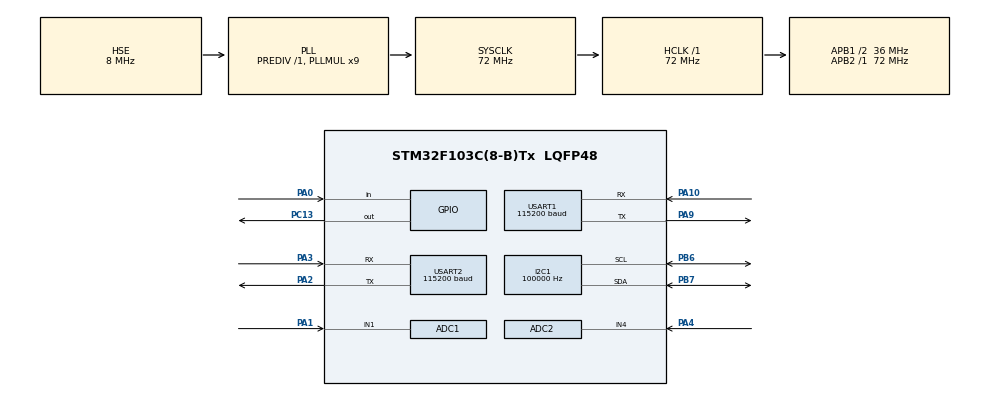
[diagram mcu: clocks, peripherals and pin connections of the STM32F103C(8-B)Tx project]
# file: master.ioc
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ADC1.Channel-0\#ChannelRegularConversion=ADC_CHANNEL_1
ADC1.ContinuousConvMode=ENABLE
ADC1.NbrOfConversionFlag=1
ADC1.Rank-0\#ChannelRegularConversion=1
ADC1.SamplingTime-0\#ChannelRegularConversion=ADC_SAMPLETIME_71CYCLES_5
ADC1.master=1
ADC2.Channel-0\#ChannelRegularConversion=ADC_CHANNEL_4
ADC2.ContinuousConvMode=ENABLE
ADC2.NbrOfConversionFlag=1
ADC2.Rank-0\#ChannelRegularConversion=1
ADC2.SamplingTime-0\#ChannelRegularConversion=ADC_SAMPLETIME_71CYCLES_5
ADC2.master=1
FREERTOS.Tasks01=defaultTask,24,128,StartDefaultTask,Default,NULL,Dynamic,NULL,NULL
FREERTOS.configCHECK_FOR_STACK_OVERFLOW=2
FREERTOS.configTOTAL_HEAP_SIZE=10240
I2C1.ClockSpeed=100000
I2C1.I2C_Mode=I2C_Fast
Mcu.Family=STM32F1
Mcu.Name=STM32F103C(8-B)Tx
Mcu.Package=LQFP48
NVIC.PriorityGroup=NVIC_PRIORITYGROUP_4
NVIC.TIM1_UP_IRQn=true\:15\:0\:false\:false\:true\:false\:false\:true\:true
NVIC.TimeBase=TIM1_UP_IRQn
NVIC.TimeBaseIP=TIM1
PA0-WKUP.GPIO_PuPd=GPIO_PULLUP
PA0-WKUP.Signal=GPIO_Input
PA1.Signal=ADCx_IN1
PA10.Mode=Asynchronous
PA10.Signal=USART1_RX
PA13.Mode=Serial_Wire
PA13.Signal=SYS_JTMS-SWDIO
PA14.Mode=Serial_Wire
PA14.Signal=SYS_JTCK-SWCLK
PA2.Mode=Asynchronous
PA2.Signal=USART2_TX
PA3.Mode=Asynchronous
PA3.Signal=USART2_RX
PA4.Signal=ADCx_IN4
PA9.Mode=Asynchronous
PA9.Signal=USART1_TX
PB6.Mode=I2C
PB6.Signal=I2C1_SCL
PB7.Mode=I2C
PB7.Signal=I2C1_SDA
PC13-TAMPER-RTC.PinState=GPIO_PIN_SET
PC13-TAMPER-RTC.Signal=GPIO_Output
PD0-OSC_IN.Mode=HSE-External-Oscillator
PD0-OSC_IN.Signal=RCC_OSC_IN
PD1-OSC_OUT.Mode=HSE-External-Oscillator
PD1-OSC_OUT.Signal=RCC_OSC_OUT
ProjectManager.HeapSize=0x200
ProjectManager.StackSize=0x400
ProjectManager.TargetToolchain=CMake
RCC.ADCPresc=RCC_ADCPCLK2_DIV6
RCC.AHBFreq_Value=72000000
RCC.APB1CLKDivider=RCC_HCLK_DIV2
RCC.APB1Freq_Value=36000000
RCC.APB1TimFreq_Value=72000000
RCC.APB2Freq_Value=72000000
RCC.APB2TimFreq_Value=72000000
RCC.HCLKFreq_Value=72000000
RCC.PLLMUL=RCC_PLL_MUL9
RCC.PLLSourceVirtual=RCC_PLLSOURCE_HSE
RCC.SYSCLKFreq_VALUE=72000000
RCC.SYSCLKSource=RCC_SYSCLKSOURCE_PLLCLK
RCC.USBFreq_Value=72000000
SH.ADCx_IN1.0=ADC1_IN1,IN1
SH.ADCx_IN4.0=ADC2_IN4,IN4
USART1.BaudRate=115200
USART1.VirtualMode=VM_ASYNC
USART2.BaudRate=115200
USART2.VirtualMode=VM_ASYNC
USART2.VirtualMode-Asynchronous=VM_ASYNC
VP_FREERTOS_VS_CMSIS_V2.Mode=CMSIS_V2
VP_SYS_VS_tim1.Mode=TIM1
board=custom

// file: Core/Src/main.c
/* USER CODE BEGIN Header */
/**
  ******************************************************************************
  * @file           : main.c
  * @brief          : Main program body
  ******************************************************************************
  * @attention
  *
  * Copyright (c) 2026 STMicroelectronics.
  * All rights reserved.
  *
  * This software is licensed under terms that can be found in the LICENSE file
  * in the root directory of this software component.
  * If no LICENSE file comes with this software, it is provided AS-IS.
  *
  ******************************************************************************
  */
/* USER CODE END Header */
#include "main.h"
#include "cmsis_os.h"
#include "adc.h"
#include "i2c.h"
#include "usart.h"
#include "gpio.h"

/* USER CODE BEGIN Includes */
#include "app.h"
#include "hwprobe.h"
/* USER CODE END Includes */

void SystemClock_Config(void);
void MX_FREERTOS_Init(void);

int main(void)
{

  /* MCU Configuration--------------------------------------------------------*/

  /* Reset of all peripherals, Initializes the Flash interface and the Systick. */
  HAL_Init();

  /* Configure the system clock */
  SystemClock_Config();

  /* Initialize all configured peripherals */
  MX_GPIO_Init();
  MX_ADC1_Init();
  MX_ADC2_Init();
  MX_USART1_UART_Init();
  MX_USART2_UART_Init();
  MX_I2C1_Init();
  /* USER CODE BEGIN 2 */
  /* 硬件自检：只在 APP_HW_PROBE=1 的版本里有实际动作，正常固件里是空语句 */
  hwprobe_run();

  /* 启动两个 ADC 的连续转换（电位器采样），此时还没进 RTOS 调度 */
  app_start_periph();
  /* USER CODE END 2 */

  /* Init scheduler */
  osKernelInitialize();  /* Call init function for freertos objects (in cmsis_os2.c) */
  MX_FREERTOS_Init();

  /* Start scheduler */
  osKernelStart();

  /* We should never get here as control is now taken by the scheduler */

  /* Infinite loop */
  while (1)
  {

  }
}

void SystemClock_Config(void)
{
  RCC_OscInitTypeDef RCC_OscInitStruct = {0};
  RCC_ClkInitTypeDef RCC_ClkInitStruct = {0};
  RCC_PeriphCLKInitTypeDef PeriphClkInit = {0};

  /** Initializes the RCC Oscillators according to the specified parameters
  * in the RCC_OscInitTypeDef structure.
  */
  RCC_OscInitStruct.OscillatorType = RCC_OSCILLATORTYPE_HSE;
  RCC_OscInitStruct.HSEState = RCC_HSE_ON;
  RCC_OscInitStruct.HSEPredivValue = RCC_HSE_PREDIV_DIV1;
  RCC_OscInitStruct.HSIState = RCC_HSI_ON;
  RCC_OscInitStruct.PLL.PLLState = RCC_PLL_ON;
  RCC_OscInitStruct.PLL.PLLSource = RCC_PLLSOURCE_HSE;
  RCC_OscInitStruct.PLL.PLLMUL = RCC_PLL_MUL9;
  if (HAL_RCC_OscConfig(&RCC_OscInitStruct) != HAL_OK)
  {
    Error_Handler();
  }

  /** Initializes the CPU, AHB and APB buses clocks
  */
  RCC_ClkInitStruct.ClockType = RCC_CLOCKTYPE_HCLK|RCC_CLOCKTYPE_SYSCLK
                              |RCC_CLOCKTYPE_PCLK1|RCC_CLOCKTYPE_PCLK2;
  RCC_ClkInitStruct.SYSCLKSource = RCC_SYSCLKSOURCE_PLLCLK;
  RCC_ClkInitStruct.AHBCLKDivider = RCC_SYSCLK_DIV1;
  RCC_ClkInitStruct.APB1CLKDivider = RCC_HCLK_DIV2;
  RCC_ClkInitStruct.APB2CLKDivider = RCC_HCLK_DIV1;

  if (HAL_RCC_ClockConfig(&RCC_ClkInitStruct, FLASH_LATENCY_2) != HAL_OK)
  {
    Error_Handler();
  }
  PeriphClkInit.PeriphClockSelection = RCC_PERIPHCLK_ADC;
  PeriphClkInit.AdcClockSelection = RCC_ADCPCLK2_DIV6;
  if (HAL_RCCEx_PeriphCLKConfig(&PeriphClkInit) != HAL_OK)
  {
    Error_Handler();
  }
}

void HAL_TIM_PeriodElapsedCallback(TIM_HandleTypeDef *htim)
{
  if (htim->Instance == TIM1)
  {
    HAL_IncTick();
  }
}

void Error_Handler(void)
{
  __disable_irq();
  while (1)
  {
  }
}

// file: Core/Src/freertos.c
/* USER CODE BEGIN Header */
/**
  ******************************************************************************
  * File Name          : freertos.c
  * Description        : Code for freertos applications
  ******************************************************************************
  * @attention
  *
  * Copyright (c) 2026 STMicroelectronics.
  * All rights reserved.
  *
  * This software is licensed under terms that can be found in the LICENSE file
  * in the root directory of this software component.
  * If no LICENSE file comes with this software, it is provided AS-IS.
  *
  ******************************************************************************
  */
/* USER CODE END Header */

#include "FreeRTOS.h"
#include "task.h"
#include "main.h"
#include "cmsis_os.h"

/* USER CODE BEGIN Includes */
#include "app.h"
/* USER CODE END Includes */

/* Definitions for defaultTask */
osThreadId_t defaultTaskHandle;
const osThreadAttr_t defaultTask_attributes = {
  .name = "defaultTask",
  .stack_size = 128 * 4,
  .priority = (osPriority_t) osPriorityNormal,
};

void StartDefaultTask(void *argument);

void MX_FREERTOS_Init(void); /* (MISRA C 2004 rule 8.1) */

/* Hook prototypes */
void vApplicationStackOverflowHook(xTaskHandle xTask, signed char *pcTaskName);

/* USER CODE BEGIN 4 */
void vApplicationStackOverflowHook(xTaskHandle xTask, signed char *pcTaskName)
{
   /* Run time stack overflow checking is performed if
   configCHECK_FOR_STACK_OVERFLOW is defined to 1 or 2. This hook function is
   called if a stack overflow is detected. */
}
/* USER CODE END 4 */

void MX_FREERTOS_Init(void) {

  /* USER CODE BEGIN RTOS_MUTEX */
  /* 创建应用互斥锁（保护主控端共享状态） */
  (void)app_init();
  /* USER CODE END RTOS_MUTEX */

  /* Create the thread(s) */
  /* creation of defaultTask */
  defaultTaskHandle = osThreadNew(StartDefaultTask, NULL, &defaultTask_attributes);

  /* USER CODE BEGIN RTOS_THREADS */
  /* 创建第五题主控端的 5 个应用任务 + 调试任务 */
  app_create_tasks();
  /* USER CODE END RTOS_THREADS */

}

void StartDefaultTask(void *argument)
{
  for(;;)
  {
    osDelay(1);
  }
}
